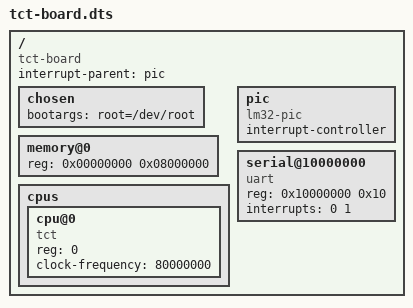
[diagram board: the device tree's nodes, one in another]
/dts-v1/;
/ {
	compatible = "tct-board";
	#addres-cells = <1>;
	#size-cells = <1>;
	interrupt-parent = <&pic>;

	chosen {
		bootargs = "root=/dev/root";
	};

	memory@0 {
		device_type = "memory";
		reg = <0x00000000 0x08000000>; /* 128+ MB */
	};

	cpus {
		#address-cells = <1>;
		#size-cells = <0>;
		cpu@0 {
			compatible = "tct";
			reg = <0>;
			clock-frequency = <80000000>; //8MHz
		};
	};

	pic: pic {
		compatible = "lm32-pic";
		#interrupt-cells = <1>;
		interrupt-controller;
	};

	serial@10000000 {
		compatible = "uart";
		reg = <0x10000000 0x10>;
		interrupts = <0 1>;
	};
}
